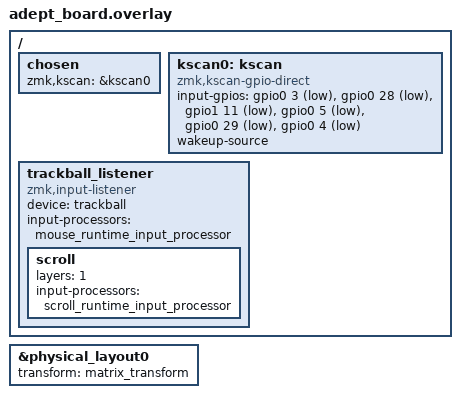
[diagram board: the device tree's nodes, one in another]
#include "adept.dtsi"
#include "pmw3610.dtsi"
#include "adept-layouts.dtsi"
#include <input/processors.dtsi>
#include <input/processors/runtime-input-processor.dtsi>
#include <dt-bindings/zmk/input_transform.h>

/* More about input processors: https://zmk.dev/docs/keymaps/input-processors#input-processors-overview */

&physical_layout0 {
    transform = <&matrix_transform>;
};

/ {
    chosen {
        zmk,kscan = &kscan0;
    };

    kscan0: kscan {
        compatible = "zmk,kscan-gpio-direct";
        input-gpios =
            <&gpio0  3 (GPIO_ACTIVE_LOW | GPIO_PULL_UP)>, // sw_1
            <&gpio0 28 (GPIO_ACTIVE_LOW | GPIO_PULL_UP)>, // sw_2
            <&gpio1 11 (GPIO_ACTIVE_LOW | GPIO_PULL_UP)>, // sw_6
            <&gpio0  5 (GPIO_ACTIVE_LOW | GPIO_PULL_UP)>, // sw_5
            <&gpio0 29 (GPIO_ACTIVE_LOW | GPIO_PULL_UP)>, // sw_3
            <&gpio0  4 (GPIO_ACTIVE_LOW | GPIO_PULL_UP)>; // sw_4
        wakeup-source;
    };

    trackball_listener { // listener for input device
        compatible = "zmk,input-listener";
        device = <&trackball>;
        input-processors =
            <&mouse_runtime_input_processor>;

        scroll {
            layers = <1>; // scroll_layer
            input-processors =
                <&scroll_runtime_input_processor>;
        };
    };
};
